VERSION ""

NS_ :

BS_:

BU_: DBG BLUETOOTH DRIVER GPS MOTOR SENSOR MASTER

BO_ 256 MASTER_MOTOR_CMD: 2 MASTER
 SG_ MASTER_MOTOR_Speed_Ctrl : 0|8@1+ (1,-100) [-100|100] "%" MOTOR,BLUETOOTH
 SG_ MASTER_MOTOR_Direction_Ctrl : 8|8@1+ (1,-100) [-100|100] "Degrees" MOTOR,BLUETOOTH

BO_ 512 SENSOR_DATA: 8 SENSOR
 SG_ SENSOR_DATA_mux M : 0|4@1+ (1,0) [0|0] "" MASTER,BLUETOOTH
 SG_ SENSOR_DATA_Sonar_Front_Left m0 : 4|10@1+ (1,0) [0|0] "cm" MASTER,BLUETOOTH
 SG_ SENSOR_DATA_Sonar_Front_Center m0 : 14|10@1+ (1,0) [0|0] "cm" MASTER,BLUETOOTH
 SG_ SENSOR_DATA_Sonar_Front_Right m0 : 24|10@1+ (1,0) [0|0] "cm" MASTER,BLUETOOTH
 SG_ SENSOR_DATA_Sonar_Rear_Left m0 : 34|10@1+ (1,0) [0|0] "cm" MASTER,BLUETOOTH
 SG_ SENSOR_DATA_Sonar_Rear_Center m0 : 44|10@1+ (1,0) [0|0] "cm" MASTER,BLUETOOTH
 SG_ SENSOR_DATA_Sonar_Rear_Right m0 : 54|10@1+ (1,0) [0|0] "cm" MASTER,BLUETOOTH
 SG_ SENSOR_DATA_Imu_Roll m1 : 4|16@1+ (1,-180) [-180|180] "degrees" BLUETOOTH
 SG_ SENSOR_DATA_Imu_Pitch m1 : 20|16@1+ (1,-180) [-180|180] "degrees" BLUETOOTH

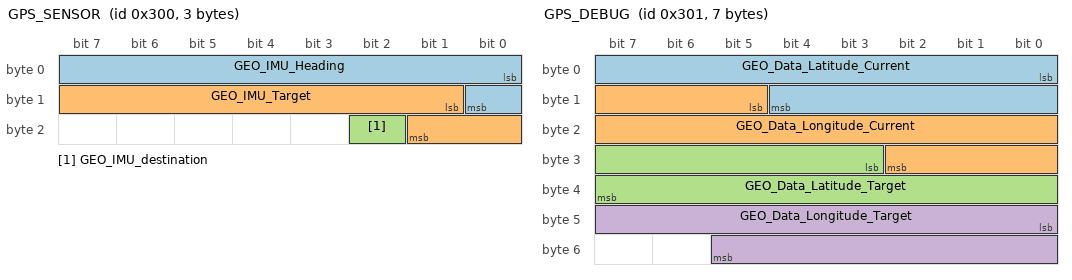
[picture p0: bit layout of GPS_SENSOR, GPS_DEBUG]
BO_ 768 GPS_SENSOR: 3 GPS
 SG_ GEO_IMU_Heading : 0|9@1+ (1,0) [0|360] "degrees" MASTER,BLUETOOTH
 SG_ GEO_IMU_Target : 9|9@1+ (1,0) [0|360] "degrees" MASTER,BLUETOOTH
 SG_ GEO_IMU_destination : 18|1@1+ (1,0) [0|0] "" MASTER,BLUETOOTH

BO_ 769 GPS_DEBUG: 7 GPS
 SG_ GEO_Data_Latitude_Current : 0|13@1+ (0.000001,37.331798) [37.331798|37.338880] "decimal_degrees" BLUETOOTH
 SG_ GEO_Data_Longitude_Current : 13|14@1+ (0.000001,-121.884988) [-121.884988|-121.876797] "decimal_degrees" BLUETOOTH
 SG_ GEO_Data_Latitude_Target : 27|13@1+ (0.000001,37.331798) [37.331798|37.338880] "decimal_degrees" BLUETOOTH
 SG_ GEO_Data_Longitude_Target : 40|14@1+ (0.000001,-121.884988) [-121.884988|-121.876797] "decimal_degrees" BLUETOOTH

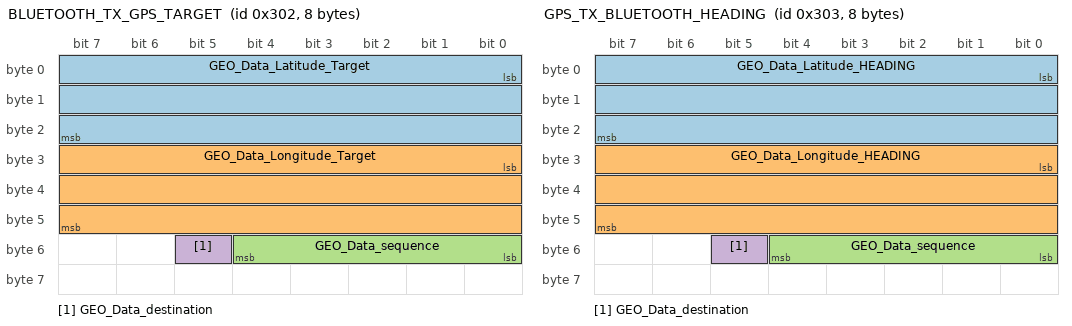
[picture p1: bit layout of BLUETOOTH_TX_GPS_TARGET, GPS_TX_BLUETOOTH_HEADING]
BO_ 770 BLUETOOTH_TX_GPS_TARGET: 8 BLUETOOTH
 SG_ GEO_Data_Latitude_Target : 0|24@1+ (1,0) [0|0] "degrees" GPS
 SG_ GEO_Data_Longitude_Target : 24|24@1+ (1,0) [0|0] "degrees" GPS
 SG_ GEO_Data_sequence : 48|5@1+ (1,0) [0|0] "" GPS
 SG_ GEO_Data_destination : 53|1@1+ (1,0) [0|0] "" GPS

BO_ 771 GPS_TX_BLUETOOTH_HEADING: 8 GPS
 SG_ GEO_Data_Latitude_HEADING : 0|24@1+ (1,0) [0|0] "degrees" BLUETOOTH
 SG_ GEO_Data_Longitude_HEADING : 24|24@1+ (1,0) [0|0] "degrees" BLUETOOTH
 SG_ GEO_Data_sequence : 48|5@1+ (1,0) [0|0] "" BLUETOOTH
 SG_ GEO_Data_destination : 53|1@1+ (1,0) [0|0] "" BLUETOOTH

BO_ 1024 MOTOR_FEEDBACK: 1 MOTOR
 SG_ MOTOR_FEEDBACK_Tachometer : 0|8@1+ (1,-100) [-100|100] "%" BLUETOOTH,DBG

BO_ 1280 BLUETOOTH_COMMAND: 4 BLUETOOTH
 SG_ GEO_Data_Latitude_Target : 0|13@1+ (0.000001,37.331798) [37.331798|37.338880] "decimal_degrees" GPS
 SG_ GEO_Data_Longitude_Target : 13|14@1+ (0.000001,-121.884988) [-121.884988|-121.876797] "decimal_degrees" GPS

CM_ BU_ BLUETOOTH "The bluetooth controller of the car";
CM_ BU_ DRIVER "The driver controller driving the car";
CM_ BU_ MOTOR "The motor controller of the car";
CM_ BU_ SENSOR "The sensor controller of the car";
CM_ BU_ GPS "The GPS controller of the car";

BA_DEF_ "BusType" STRING ;
BA_DEF_ BO_ "GenMsgCycleTime" INT 0 0;
BA_DEF_ SG_ "FieldType" STRING ;

BA_DEF_DEF_ "BusType" "CAN";
BA_DEF_DEF_ "FieldType" "";
BA_DEF_DEF_ "GenMsgCycleTime" 0;

BA_ "GenMsgCycleTime" BO_ 256 10;
BA_ "GenMsgCycleTime" BO_ 512 10;
BA_ "GenMsgCycleTime" BO_ 768 500;
BA_ "GenMsgCycleTime" BO_ 1024 100;
BA_ "GenMsgCycleTime" BO_ 1280 1000;

BA_ "FieldType" SG_ 200 SENSOR_DATA_mux "SENSOR_DATA_mux";

VAL_ 512 SENSOR_DATA_mux 0 "SENSOR_DATA_SONAR" 1 "SENSOR_DATA_DIRECTION" ;
